# STM32L4A6xx register map
File version: 1.0
Registers are 32-bit, read-write, reset 0x0 unless marked. A register's access mark holds for its fields unless they carry their own. Offsets are from the block's base; [hi:lo] are bit positions; {n}, {i} and the like mark numbered series.

## OPAMP2 — Operational Amplifier (OPAMP)
Base 0x40007810
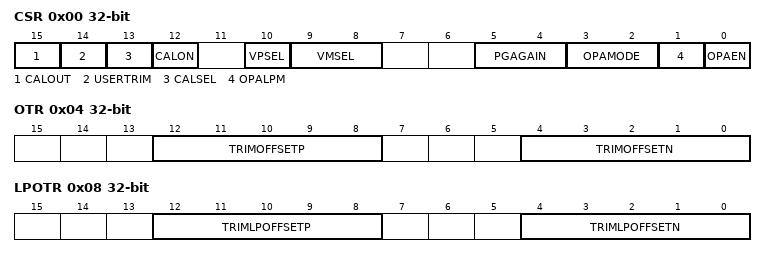
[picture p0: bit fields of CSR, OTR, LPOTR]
0x00 CSR — OPAMP control/status register
  [15] CALOUT — Operational amplifier2 calibration output
  [14] USERTRIM — User trimming enable
  [13] CALSEL — Calibration selection
  [12] CALON — Calibration mode enable
  [10] VPSEL — Non inverted input selection
  [9:8] VMSEL — Inverting input selection
  [5:4] PGAGAIN — Operational amplifier2 Programmable amplifier gain value
  [3:2] OPAMODE — Operational amplifier2 PGA mode
  [1] OPALPM — Operational amplifier2 Low Power Mode
  [0] OPAEN — Operational amplifier2 Enable
0x04 OTR — OPAMP
  [12:8] TRIMOFFSETP — Trim for PMOS differential pairs
  [4:0] TRIMOFFSETN — Trim for NMOS differential pairs
0x08 LPOTR — OPAMP
  [12:8] TRIMLPOFFSETP — Trim for PMOS differential pairs
  [4:0] TRIMLPOFFSETN — Trim for NMOS differential pairs

## SWPMI1 — Single Wire Protocol Master Interface SPWMI
Base 0x40008800
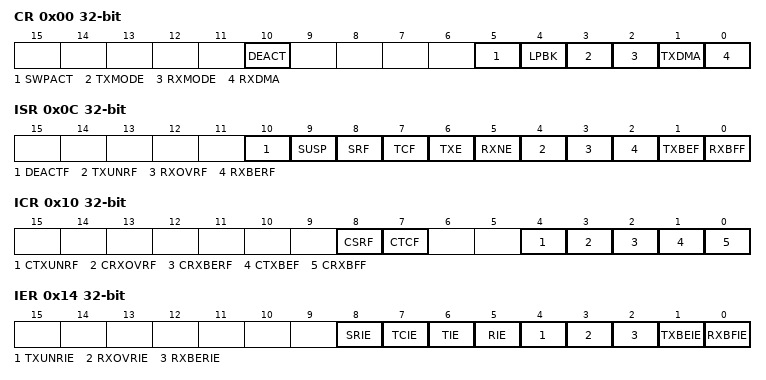
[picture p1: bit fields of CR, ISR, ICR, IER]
0x00 CR — SWPMI Configuration/Control register
  [10] DEACT — Single wire protocol master interface deactivate
  [5] SWPACT — Single wire protocol master interface activate
  [4] LPBK — Loopback mode enable
  [3] TXMODE — Transmission buffering mode
    0=SINGLE (Single software buffer mode for transmission); 1=MULTI (Multi software buffermode for transmission)
  [2] RXMODE — Reception buffering mode
    0=SINGLE (Single software buffer mode for reception); 1=MULTI (Multi software buffermode for reception)
  [1] TXDMA — Transmission DMA enable
  [0] RXDMA — Reception DMA enable
0x04 BRR — SWPMI bitrate register
  [5:0] BR — BR[5:0] bits (Bitrate prescaler)
0x0C ISR — SWPMI Interrupt and Status register
  [10] DEACTF — DEACTIVATED flag
  [9] SUSP — SUSPEND flag
  [8] SRF — Slave resume flag
  [7] TCF — Transfer complete flag
  [6] TXE — Transmit data register empty
  [5] RXNE — Receive data register not empty
  [4] TXUNRF — Transmit underrun error flag
  [3] RXOVRF — Receive overrun error flag
  [2] RXBERF — Receive CRC error flag
  [1] TXBEF — Transmit buffer empty flag
  [0] RXBFF — Receive buffer full flag
0x10 ICR — SWPMI Interrupt Flag Clear register
  [8] CSRF — Clear slave resume flag
  [7] CTCF — Clear transfer complete flag
  [4] CTXUNRF — Clear transmit underrun error flag
  [3] CRXOVRF — Clear receive overrun error flag
  [2] CRXBERF — Clear receive CRC error flag
  [1] CTXBEF — Clear transmit buffer empty flag
  [0] CRXBFF — Clear receive buffer full flag
0x14 IER — SWPMI Interrupt Enable register
  [8] SRIE — Slave resume interrupt enable
  [7] TCIE — Transmit complete interrupt enable
  [6] TIE — Transmit interrupt enable
  [5] RIE — Receive interrupt enable
  [4] TXUNRIE — Transmit underrun error interrupt enable
  [3] RXOVRIE — Receive overrun error interrupt enable
  [2] RXBERIE — Receive CRC error interrupt enable
  [1] TXBEIE — Transmit buffer empty interrupt enable
  [0] RXBFIE — Receive buffer full interrupt enable
0x18 RFL — SWPMI Receive Frame Length register
  [4:0] RFL — RFL[4:0] bits (Receive Frame length)
0x1C TDR — SWPMI Transmit data register
  [31:0] TD — Transmit Data Register
0x20 RDR — SWPMI Receive data register
  [31:0] RD — Receive Data Register
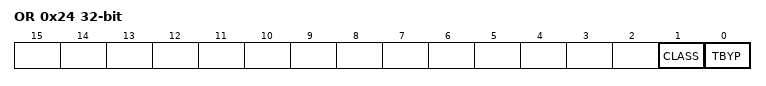
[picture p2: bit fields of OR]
0x24 OR — SWPMI Option register
  [1] CLASS — SWP Voltage Class selection
    0=C (SWPMI_IO uses directly VDD voltage to operate in class C); 1=B (SWPMI_IO uses an internal voltage regulator to operate in class B)
  [0] TBYP — SWP Transceiver Bypass

## SYSCFG — System configuration controller
Base 0x40010000
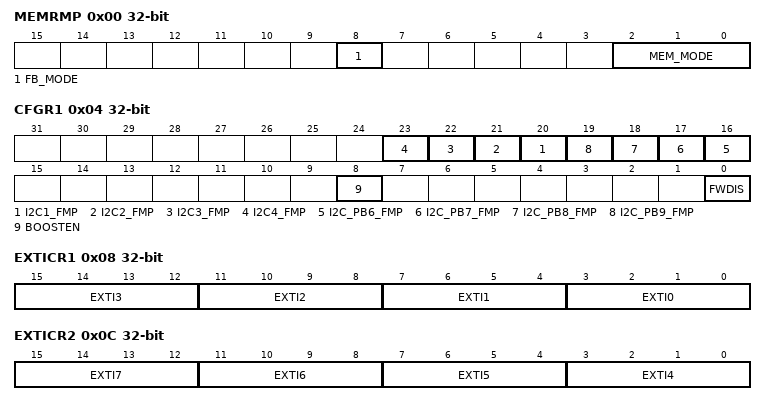
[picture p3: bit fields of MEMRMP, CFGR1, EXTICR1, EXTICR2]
0x00 MEMRMP — SYSCFG memory remap register
  [8] FB_MODE — Flash Bank mode selection
    0=BANK1; 1=BANK2
  [2:0] MEM_MODE — SYSCFG_Memory Remap Config
    0=FLASH (Main Flash memory mapped at 0x00000000); 1=SYSTEMFLASH (System Flash memory mapped at 0x00000000); 3=SRAM (SRAM1 mapped at 0x00000000); 2=FMC (FMC bank 1 (NOR/PSRAM 1 and 2) mapped at 0x00000000); 6=QUADSPI (QUADSPI memory mapped at 0x00000000)
0x04 CFGR1 — SYSCFG configuration register 1
  [n+19] I2C{n}_FMP (n=1..4) — I2C{n} Fast mode plus
  [n+10] I2C_PB{n}_FMP (n=6..9) — I2C PB{n} Fast mode plus
  [8] BOOSTEN — I/O analog switch voltage booster enable
  [0] FWDIS — FIREWALL access enable
0x08 EXTICR1 — SYSCFG external interrupt configuration registers
  [4n+3:4n] EXTI{n} (n=0..3) — EXTI {n} configuration
0x0C EXTICR2 — SYSCFG external interrupt configuration registers
  [4n-13:4n-16] EXTI{n} (n=4..7) — EXTI {n} configuration
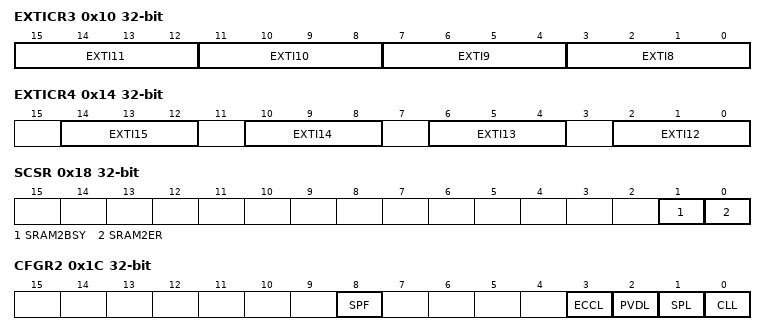
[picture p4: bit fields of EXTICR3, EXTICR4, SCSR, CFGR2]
0x10 EXTICR3 — SYSCFG external interrupt configuration registers
  [4n-29:4n-32] EXTI{n} (n=8..11) — EXTI {n} configuration
0x14 EXTICR4 — SYSCFG external interrupt configuration registers
  [4n-46:4n-48] EXTI{n} (n=12..15) — EXTI {n} configuration
0x18 SCSR — SYSCFG SRAM2 control and status register
  [1] SRAM2BSY — SRAM2 Erase Ongoing
  [0] SRAM2ER — SRAM2 Erase Request
0x1C CFGR2 — SYSCFG configuration register 2
  [8] SPF — SRAM Parity Flag
  [3] ECCL — ECC Lock
  [2] PVDL — PVD Lock
  [1] SPL — SRAM Parity Lock
  [0] CLL — Core Lockup Lock
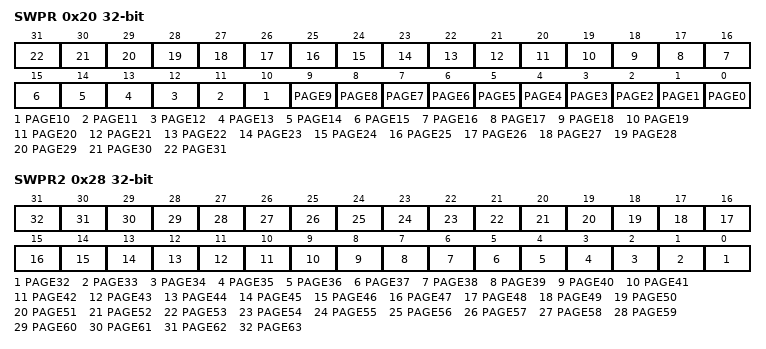
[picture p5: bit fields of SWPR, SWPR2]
0x20 SWPR — SYSCFG SRAM2 write protection register
  [n] PAGE{n} (n=0..31) — SRAM2 Write protection page {n}
0x24 SKR — SYSCFG SRAM2 key register
  [7:0] KEY — SRAM2 write protection key for software erase
0x28 SWPR2 — SYSCFG SRAM2 write protection register 2
  [n-32] PAGE{n} (n=32..63) — SRAM2 Write protection page {n}
